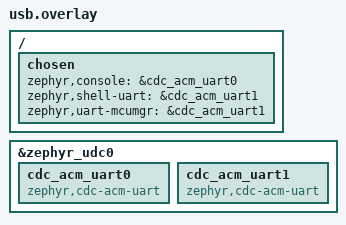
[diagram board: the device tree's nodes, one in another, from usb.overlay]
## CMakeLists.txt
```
cmake_minimum_required(VERSION 3.20.0)

# Top-level CMakeLists.txt for the skeleton application.
#
# Copyright (c) 2017 Open Source Foundries Limited
#
# SPDX-License-Identifier: Apache-2.0
#
# This provides a basic application structure suitable for communication using
# mcumgr.  It can be used as a starting point for new applications.

# Standard Zephyr application boilerplate.
find_package(Zephyr REQUIRED HINTS $ENV{ZEPHYR_BASE})
project(smp_svr)

target_sources(app PRIVATE src/main.c)
target_sources_ifdef(CONFIG_MCUMGR_TRANSPORT_BT app PRIVATE src/bluetooth.c)
target_sources_ifdef(CONFIG_SHELL app PRIVATE src/shell.c)
```

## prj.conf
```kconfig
# Enable MCUmgr and dependencies.
CONFIG_NET_BUF=y
CONFIG_ZCBOR=y
CONFIG_CRC=y
CONFIG_MCUMGR=y
CONFIG_STREAM_FLASH=y
CONFIG_FLASH_MAP=y

# Some command handlers require a large stack.
CONFIG_SYSTEM_WORKQUEUE_STACK_SIZE=2304
CONFIG_MAIN_STACK_SIZE=2048

# Ensure an MCUboot-compatible binary is generated.
CONFIG_BOOTLOADER_MCUBOOT=y

# Correct version config
CONFIG_FW_INFO=y
CONFIG_FW_INFO_FIRMWARE_VERSION=0

# Enable flash operations.
CONFIG_FLASH=y

# Required by the `taskstat` command.
CONFIG_THREAD_MONITOR=y

# Support for taskstat command
CONFIG_MCUMGR_GRP_OS_TASKSTAT=y

# Enable statistics and statistic names.
CONFIG_STATS=y
CONFIG_STATS_NAMES=y

# Enable most core commands.
CONFIG_FLASH=y
CONFIG_IMG_MANAGER=y
CONFIG_MCUMGR_GRP_IMG=y
CONFIG_MCUMGR_GRP_OS=y
CONFIG_MCUMGR_GRP_STAT=y

# Enable logging
CONFIG_LOG=n
CONFIG_MCUBOOT_UTIL_LOG_LEVEL_WRN=n

# Disable debug logging
CONFIG_LOG_MAX_LEVEL=3
```

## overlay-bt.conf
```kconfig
CONFIG_BT=y
CONFIG_BT_PERIPHERAL=y

# Allow for large Bluetooth data packets.
CONFIG_BT_L2CAP_TX_MTU=498
CONFIG_BT_BUF_ACL_RX_SIZE=502
CONFIG_BT_BUF_ACL_TX_SIZE=502
CONFIG_BT_CTLR_DATA_LENGTH_MAX=251

# Enable the Bluetooth mcumgr transport (unauthenticated).
CONFIG_MCUMGR_TRANSPORT_BT=y
CONFIG_MCUMGR_TRANSPORT_BT_CONN_PARAM_CONTROL=y

# Enable the Shell mcumgr transport.
CONFIG_BASE64=y
CONFIG_CRC=y
CONFIG_SHELL=y
CONFIG_SHELL_BACKEND_SERIAL=y
CONFIG_MCUMGR_TRANSPORT_SHELL=y

# Enable the mcumgr Packet Reassembly feature over Bluetooth and its configuration dependencies.
# MCUmgr buffer size is optimized to fit one SMP packet divided into five Bluetooth Write Commands,
# transmitted with the maximum possible MTU value: 498 bytes.
CONFIG_MCUMGR_TRANSPORT_BT_REASSEMBLY=y
CONFIG_MCUMGR_TRANSPORT_NETBUF_SIZE=2475
CONFIG_MCUMGR_GRP_OS_MCUMGR_PARAMS=y
CONFIG_MCUMGR_TRANSPORT_WORKQUEUE_STACK_SIZE=4608

# Enable the LittleFS file system.
CONFIG_FILE_SYSTEM=y
CONFIG_FILE_SYSTEM_LITTLEFS=y

# Enable file system commands
CONFIG_MCUMGR_GRP_FS=y

# Enable the storage erase command.
CONFIG_MCUMGR_GRP_ZBASIC=y
CONFIG_MCUMGR_GRP_ZBASIC_STORAGE_ERASE=y

# Disable Bluetooth ping support
CONFIG_BT_CTLR_LE_PING=n

# Disable shell commands that are not needed
CONFIG_CLOCK_CONTROL_NRF_SHELL=n
CONFIG_DEVICE_SHELL=n
CONFIG_DEVMEM_SHELL=n
CONFIG_FLASH_SHELL=n
```

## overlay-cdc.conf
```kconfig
# Enable USB subsystem
CONFIG_USB_DEVICE_STACK=y
CONFIG_SERIAL=y
CONFIG_UART_LINE_CTRL=y
CONFIG_USB_DEVICE_INITIALIZE_AT_BOOT=y
CONFIG_USB_CDC_ACM=y
CONFIG_USB_DEVICE_PRODUCT="nRF USB"
CONFIG_CONSOLE=y

# MCUmgr with UART transport
CONFIG_MCUMGR=y
CONFIG_MCUMGR_TRANSPORT_UART=y
CONFIG_MCUMGR_GRP_OS=y
CONFIG_MCUMGR_GRP_IMG=y
CONFIG_MCUMGR_GRP_STAT=y

# Shell support
CONFIG_SHELL=y
CONFIG_SHELL_BACKEND_SERIAL=y

# Required dependencies
CONFIG_BASE64=y
CONFIG_CRC=y
CONFIG_ZCBOR=y

# Logging
CONFIG_LOG=y
```

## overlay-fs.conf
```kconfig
# Enable the LittleFS file system.
CONFIG_FLASH_MAP=y
CONFIG_FILE_SYSTEM=y
CONFIG_FILE_SYSTEM_LITTLEFS=y

# Add 256 bytes to accommodate upload command (lfs_stat overflows)
CONFIG_SYSTEM_WORKQUEUE_STACK_SIZE=2304

# Enable file system commands
CONFIG_MCUMGR_GRP_FS=y
```

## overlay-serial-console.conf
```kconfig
# Enable console with MCUmgr pass through
CONFIG_BASE64=y
CONFIG_CRC=y
CONFIG_CONSOLE=y
CONFIG_UART_CONSOLE=y
CONFIG_UART_CONSOLE_MCUMGR=y
```

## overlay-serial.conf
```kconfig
# Enable the serial MCUmgr transport.
CONFIG_BASE64=y
CONFIG_CRC=y
CONFIG_MCUMGR_TRANSPORT_UART=y
CONFIG_CONSOLE=y
```

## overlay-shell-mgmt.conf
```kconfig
# Enable shell commands.
CONFIG_BASE64=y
CONFIG_CRC=y
CONFIG_SHELL=y
CONFIG_SHELL_BACKEND_DUMMY=y
CONFIG_MCUMGR_GRP_SHELL=y
```

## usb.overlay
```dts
/ {
    chosen {
        zephyr,console = &cdc_acm_uart0;      /* Console/logging on ACM0 */
        zephyr,shell-uart = &cdc_acm_uart1;   /* Shell on ACM1 */
        zephyr,uart-mcumgr = &cdc_acm_uart1;  /* MCUmgr also on ACM1 */
    };
};

&zephyr_udc0 {
    cdc_acm_uart0: cdc_acm_uart0 {
        compatible = "zephyr,cdc-acm-uart";
    };
    cdc_acm_uart1: cdc_acm_uart1 {
        compatible = "zephyr,cdc-acm-uart";
    };
};
```

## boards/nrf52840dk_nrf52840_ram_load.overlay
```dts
/delete-node/ &sram0;

#include "../sysbuild/nrf52840dk_nrf52840_mcuboot_ram_load.overlay"

/ {
	chosen {
		zephyr,flash = &flash0;
		/delete-property/ zephyr,code-partition;
	};

	soc {
		sram0: memory@20006000 {
			compatible = "mmio-sram";
			reg = <0x20006000 DT_SIZE_K(200)>;
		};
	};
};
```

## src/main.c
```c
/*
 * Copyright (c) 2012-2014 Wind River Systems, Inc.
 * Copyright (c) 2020 Prevas A/S
 *
 * SPDX-License-Identifier: Apache-2.0
 */

#include <zephyr/kernel.h>
#include <zephyr/stats/stats.h>
#include <zephyr/usb/usb_device.h>

#ifdef CONFIG_MCUMGR_GRP_FS
#include <zephyr/device.h>
#include <zephyr/fs/fs.h>
#include <zephyr/fs/littlefs.h>
#endif
#ifdef CONFIG_MCUMGR_GRP_STAT
#include <zephyr/mgmt/mcumgr/grp/stat_mgmt/stat_mgmt.h>
#endif

#define LOG_LEVEL LOG_LEVEL_DBG
#include <zephyr/logging/log.h>
LOG_MODULE_REGISTER(smp_sample);

#include "common.h"

#define STORAGE_PARTITION_LABEL	storage_partition
#define STORAGE_PARTITION_ID	FIXED_PARTITION_ID(STORAGE_PARTITION_LABEL)

/* Define an example stats group; approximates seconds since boot. */
STATS_SECT_START(smp_svr_stats)
STATS_SECT_ENTRY(ticks)
STATS_SECT_END;

/* Assign a name to the `ticks` stat. */
STATS_NAME_START(smp_svr_stats)
STATS_NAME(smp_svr_stats, ticks)
STATS_NAME_END(smp_svr_stats);

/* Define an instance of the stats group. */
STATS_SECT_DECL(smp_svr_stats) smp_svr_stats;

#ifdef CONFIG_MCUMGR_GRP_FS
FS_LITTLEFS_DECLARE_DEFAULT_CONFIG(cstorage);
static struct fs_mount_t littlefs_mnt = {
	.type = FS_LITTLEFS,
	.fs_data = &cstorage,
	.storage_dev = (void *)STORAGE_PARTITION_ID,
	.mnt_point = "/lfs1"
};
#endif

int main(void)
{
	printk("App v2.0.0 running!\n");
	int rc = STATS_INIT_AND_REG(smp_svr_stats, STATS_SIZE_32,
				    "smp_svr_stats");

	if (rc < 0) {
		LOG_ERR("Error initializing stats system [%d]", rc);
	}

	/* Register the built-in mcumgr command handlers. */
#ifdef CONFIG_MCUMGR_GRP_FS
	rc = fs_mount(&littlefs_mnt);
	if (rc < 0) {
		LOG_ERR("Error mounting littlefs [%d]", rc);
	}
#endif

#ifdef CONFIG_MCUMGR_TRANSPORT_BT
	start_smp_bluetooth_adverts();
#endif

	if (IS_ENABLED(CONFIG_USB_DEVICE_STACK)) {
		rc = usb_enable(NULL);

		/* Ignore EALREADY error as USB CDC is likely already initialised */
		if (rc != 0 && rc != -EALREADY) {
			LOG_ERR("Failed to enable USB");
			return 0;
		}
	}
	/* using __TIME__ ensure that a new binary will be built on every
	 * compile which is convenient when testing firmware upgrade.
	 */
	LOG_INF("build time: " __DATE__ " " __TIME__);
	

	/* The system work queue handles all incoming mcumgr requests.  Let the
	 * main thread idle while the mcumgr server runs.
	 */
	while (1) {
		k_sleep(K_MSEC(1000));
		STATS_INC(smp_svr_stats, ticks);
	}
	return 0;
}
```

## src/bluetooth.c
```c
/*
 * Copyright (c) 2012-2014 Wind River Systems, Inc.
 * Copyright (c) 2020 Prevas A/S
 *
 * SPDX-License-Identifier: Apache-2.0
 */

#include <zephyr/bluetooth/bluetooth.h>
#include <zephyr/bluetooth/conn.h>
#include <zephyr/bluetooth/gatt.h>
#include <zephyr/bluetooth/hci.h>
#include <zephyr/mgmt/mcumgr/transport/smp_bt.h>

#define LOG_LEVEL LOG_LEVEL_DBG
#include <zephyr/logging/log.h>
LOG_MODULE_REGISTER(smp_bt_sample);

static struct k_work advertise_work;

static const struct bt_data ad[] = {
	BT_DATA_BYTES(BT_DATA_FLAGS, (BT_LE_AD_GENERAL | BT_LE_AD_NO_BREDR)),
	BT_DATA_BYTES(BT_DATA_UUID128_ALL, SMP_BT_SVC_UUID_VAL),
};

static const struct bt_data sd[] = {
	BT_DATA(BT_DATA_NAME_COMPLETE, CONFIG_BT_DEVICE_NAME, sizeof(CONFIG_BT_DEVICE_NAME) - 1),
};

static void advertise(struct k_work *work)
{
	int rc;

	rc = bt_le_adv_start(BT_LE_ADV_CONN_FAST_1, ad, ARRAY_SIZE(ad), sd, ARRAY_SIZE(sd));
	if (rc) {
		LOG_ERR("Advertising failed to start (rc %d)", rc);
		return;
	}

	LOG_INF("Advertising successfully started");
}

static void connected(struct bt_conn *conn, uint8_t err)
{
	if (err) {
		LOG_ERR("Connection failed, err 0x%02x %s", err, bt_hci_err_to_str(err));
		k_work_submit(&advertise_work);
	} else {
		LOG_INF("Connected");
	}
}

static void disconnected(struct bt_conn *conn, uint8_t reason)
{
	LOG_INF("Disconnected, reason 0x%02x %s", reason, bt_hci_err_to_str(reason));
}

static void on_conn_recycled(void)
{
	k_work_submit(&advertise_work);
}

BT_CONN_CB_DEFINE(conn_callbacks) = {
	.connected = connected,
	.disconnected = disconnected,
	.recycled = on_conn_recycled,
};

static void bt_ready(int err)
{
	if (err != 0) {
		LOG_ERR("Bluetooth failed to initialise: %d", err);
	} else {
		k_work_submit(&advertise_work);
	}
}

void start_smp_bluetooth_adverts(void)
{
	int rc;

	k_work_init(&advertise_work, advertise);
	rc = bt_enable(bt_ready);

	if (rc != 0) {
		LOG_ERR("Bluetooth enable failed: %d", rc);
	}
}
```

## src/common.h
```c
/*
 * Copyright (c) 2020 Prevas A/S
 *
 * SPDX-License-Identifier: Apache-2.0
 */

void start_smp_bluetooth_adverts(void);
```

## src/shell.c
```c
#include <zephyr/kernel.h>
#include <zephyr/shell/shell.h>
#include <zephyr/device.h>
#include <zephyr/devicetree.h>
#include <zephyr/sys/printk.h>
#include <zephyr/version.h>

static int cmd_hello(const struct shell *shell, size_t argc, char **argv) {
    shell_print(shell, "Hello, Zephyr Shell!");
    return 0;
}

static int listall(const struct shell *shell, size_t argc, char **argv) {
    shell_print(shell, "=== Device Information ===");
    
    // System Information
    shell_print(shell, "\n--- System Info ---");
    shell_print(shell, "Board: %s", CONFIG_BOARD);
    shell_print(shell, "SoC: %s", CONFIG_SOC);
    shell_print(shell, "Zephyr Version: %s", KERNEL_VERSION_STRING);
    shell_print(shell, "Build Time: %s %s", __DATE__, __TIME__);
    
    // Runtime Information
    shell_print(shell, "\n--- Runtime Info ---");
    shell_print(shell, "Uptime: %lld ms", k_uptime_get());
    shell_print(shell, "CPU Frequency: %d Hz", sys_clock_hw_cycles_per_sec());

#ifdef CONFIG_NETWORKING
    shell_print(shell, "\n--- Network Info ---");
    shell_print(shell, "Networking: Enabled");
#ifdef CONFIG_MCUMGR_TRANSPORT_UDP
    shell_print(shell, "UDP Transport: Enabled (Port 1337)");
#endif
#else
    shell_print(shell, "\n--- Network Info ---");
    shell_print(shell, "Networking: Disabled");
#endif

    // MCUmgr Information
    shell_print(shell, "\n--- MCUmgr Info ---");
#ifdef CONFIG_MCUMGR_TRANSPORT_UART
    shell_print(shell, "UART Transport: Enabled");
#endif
#ifdef CONFIG_MCUMGR_TRANSPORT_BT
    shell_print(shell, "Bluetooth Transport: Enabled");
#endif

    // Hardware Information
    shell_print(shell, "\n--- Hardware Info ---");
    shell_print(shell, "Board: %s", CONFIG_BOARD);
    
    shell_print(shell, "\n=== End Device Info ===");
    return 0;
}

// Register shell commands
SHELL_CMD_REGISTER(hello, NULL, "Say hello", cmd_hello);
SHELL_CMD_REGISTER(listall, NULL, "List all device information", listall);
```
